# FM33LE0XXA register map
File version: 1.0
CPU: SC000 r1p0, little endian, no MPU, no FPU, 3 interrupt priority bits
Registers are 32-bit, read-write, reset 0x0 unless marked. A register's access mark holds for its fields unless they carry their own. Offsets are from the block's base; [hi:lo] are bit positions; {n}, {i} and the like mark numbered series.

## ADC — ADC module information
Base 0x4001AC00
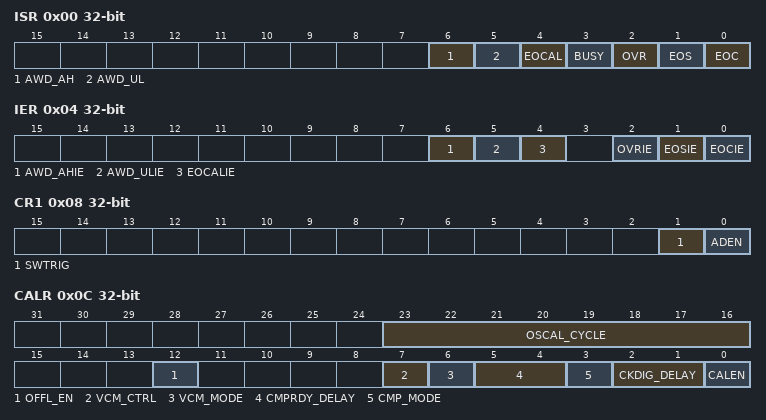
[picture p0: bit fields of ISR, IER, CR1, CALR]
0x00 ISR access per field — ADC Interrupt and Status Register
  [6] AWD_AH rw — AWD_AH field description
  [5] AWD_UL rw — AWD_UL field description
  [4] EOCAL rw — EOCAL field description
  [3] BUSY ro — BUSY field description
  [2] OVR rw — OVR field description
  [1] EOS rw — EOS field description
  [0] EOC rw — EOC field description
0x04 IER — ADC Interrupt Enable Register
  [6] AWD_AHIE — AWD_AHIE field description
  [5] AWD_ULIE — AWD_ULIE field description
  [4] EOCALIE — EOCALIE field description
  [2] OVRIE — OVRIE field description
  [1] EOSIE — EOSIE field description
  [0] EOCIE — EOCIE field description
0x08 CR1 — ADC Control Register1
  [1] SWTRIG — SWTRIG field description
  [0] ADEN — ADEN field description
0x0C CALR — ADC Calibration Register
  [23:16] OSCAL_CYCLE — OSCAL_CYCLE field description
  [12] OFFL_EN — OFFL_EN field description
  [7] VCM_CTRL — VCM_CTRL field description
  [6] VCM_MODE — VCM_MODE field description
  [5:4] CMPRDY_DELAY — CMPRDY_DELAY field description
  [3] CMP_MODE — CMP_MODE field description
  [2:1] CKDIG_DELAY — CKDIG_DELAY field description
  [0] CALEN — CALEN field description
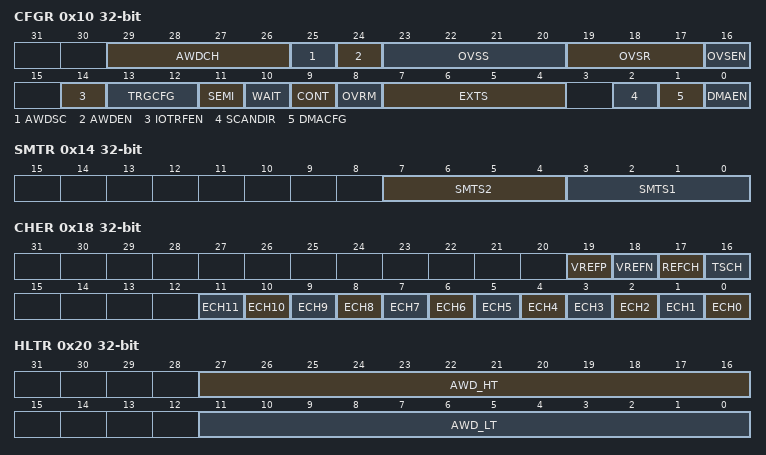
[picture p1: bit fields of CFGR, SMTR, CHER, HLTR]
0x10 CFGR — ADC Config Register
  [29:26] AWDCH — AWDCH field description
  [25] AWDSC — AWDSC field description
  [24] AWDEN — AWDEN field description
  [23:20] OVSS — OVSS field description
  [19:17] OVSR — OVSR field description
  [16] OVSEN — OVSEN field description
  [14] IOTRFEN — IOTRFEN field description
  [13:12] TRGCFG — TRGCFG field description
  [11] SEMI — SEMI field description
  [10] WAIT — WAIT field description
  [9] CONT — CONT field description
  [8] OVRM — OVRM field description
  [7:4] EXTS — EXTS field description
  [2] SCANDIR — SCANDIR field description
  [1] DMACFG — DMACFG field description
  [0] DMAEN — DMAEN field description
0x14 SMTR — ADC Sampling Time Register
  [7:4] SMTS2 — SMTS2 field description
  [3:0] SMTS1 — SMTS1 field description
0x18 CHER — ADC Channel Enable Register
  [19] VREFP — VREFP field description
  [18] VREFN — VREFN field description
  [17] REFCH — REFCH field description
  [16] TSCH — TSCH field description
  [n] ECH{n} (n=0..11) — ECH{n} field description
0x1C DR ro — ADC Data Register
  [15:0] DATA — DATA field description
0x20 HLTR — ADC analog watchdog Threshold Register
  [27:16] AWD_HT — AWD_HT field description
  [11:0] AWD_LT — AWD_LT field description
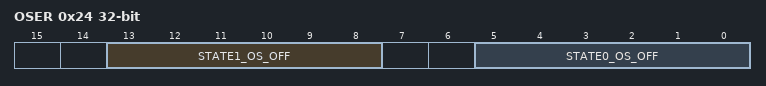
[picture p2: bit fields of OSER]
0x24 OSER
  [13:8] STATE1_OS_OFF — STATE1_OS_OFF field description
  [5:0] STATE0_OS_OFF — STATE0_OS_OFF field description

## GPIOA — GPIOA module information
Base 0x40000C00
Same registers: GPIOB 0x40000C40, GPIOC 0x40000C80, GPIOD 0x40000CC0
0x00 INEN — GPIOA Input Enable Register
  [15:0] INEN — INEN field description
0x04 PUEN — GPIOA Pull-Up Enable Register
  [15:0] PUEN — PUEN field description
0x08 ODEN — GPIOA Open-Drain Enable Register
  [15:0] ODEN — ODEN field description
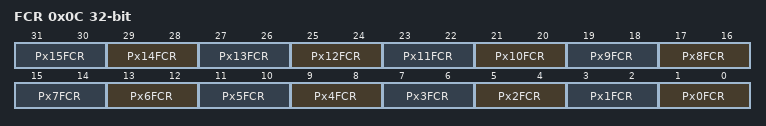
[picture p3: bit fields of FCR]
0x0C FCR — GPIOA Function Control Register
  [2n+1:2n] Px{n}FCR (n=0..15) — Px{n}FCR field description
0x10 DO — GPIOA Data Output Register
  [15:0] DO — DO field description
0x14 DSET wo — GPIOA Data Set Register
  [15:0] DSET — DSET field description
0x18 DRST wo — GPIOA Data Reset Register
  [15:0] DRESET — DRESET field description
0x1C DIN ro — GPIOA Data Input Register
  [15:0] DIN — DIN field description
0x20 DFS — GPIOA Digital Function Select
  [15:0] DFS — DFS field description
0x28 ANEN — GPIOAAnalog channel Enable Register
  [15:0] ANEN — ANEN field description

## GPIO — GPIO module information
Base 0x40000D00
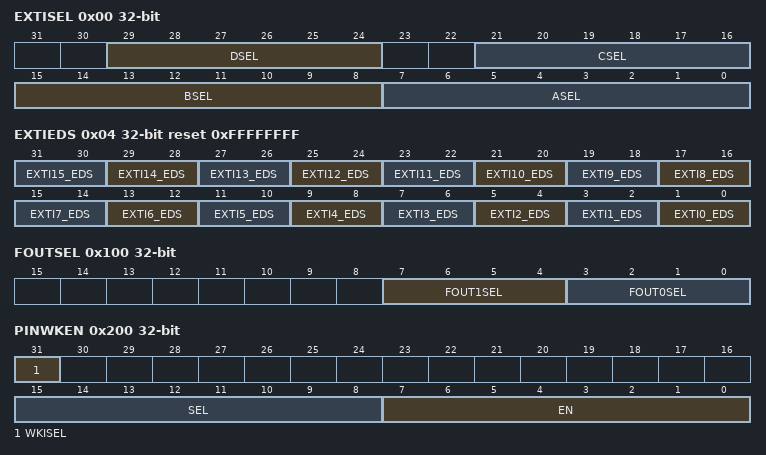
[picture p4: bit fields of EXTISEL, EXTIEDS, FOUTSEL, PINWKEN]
0x00 EXTISEL — External Interrupt input Select Register
  [29:24] DSEL — DSEL field description
  [21:16] CSEL — CSEL field description
  [15:8] BSEL — BSEL field description
  [7:0] ASEL — ASEL field description
0x04 EXTIEDS reset 0xFFFFFFFF — External Interrupt Edge Select and Enable Register
  [2n+1:2n] EXTI{n}_EDS (n=0..15) — EXTI{n}_EDS field description
0x08 EXTIDF — External Interrupt Digital Filter Register
  [15:0] DF — DF field description
0x0C EXTIISR — External Interrupt and Status Register
  [15:0] IF — IF field description
0x10 EXTIDI ro — External Interrupt Data Input Register
  [15:0] DI — DI field description
0x100 FOUTSEL — Frequency Output Select Register
  [7:4] FOUT1SEL — FOUT1SEL field description
  [3:0] FOUT0SEL — FOUT0SEL field description
0x200 PINWKEN — Wakeup Enable Register
  [31] WKISEL — WKISEL field description
  [15:8] SEL — SEL field description
  [7:0] EN — EN field description
